# RP2040 register map
Vendor: Raspberry Pi; Series: RP; File version: 0.1
CPU: CM0PLUS r0p1, little endian, MPU, no FPU, VTOR, 2 interrupt priority bits, 32 interrupts
Registers are 32-bit, read-write, reset 0x0 unless marked. A register's access mark holds for its fields unless they carry their own. Offsets are from the block's base; [hi:lo] are bit positions; {n}, {i} and the like mark numbered series; 'fields as' and 'values as' point back to an identical list; <NAME> marks a mode.

## PADS_BANK0
Base 0x4001C000
0x00 VOLTAGE_SELECT — Voltage select. Per bank control
  [0] VOLTAGE_SELECT
    0=3v3 (Set voltage to 3.3V (DVDD >= 2V5)); 1=1v8 (Set voltage to 1.8V (DVDD <= 1V8))
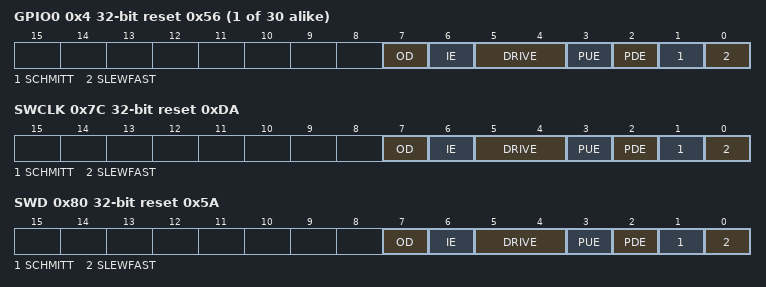
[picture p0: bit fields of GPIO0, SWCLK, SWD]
{0x4+4i} GPIO{i} reset 0x56 (i=0..29) — Pad control register
  [7] OD — Output disable. Has priority over output enable from peripherals
  [6] IE — Input enable
  [5:4] DRIVE — Drive strength.
    0=2mA; 1=4mA; 2=8mA; 3=12mA
  [3] PUE — Pull up enable
  [2] PDE — Pull down enable
  [1] SCHMITT — Enable schmitt trigger
  [0] SLEWFAST — Slew rate control. 1 = Fast, 0 = Slow
0x7C SWCLK reset 0xDA — Pad control register
  fields as GPIO0
0x80 SWD reset 0x5A — Pad control register
  fields as GPIO0

## PADS_QSPI
Base 0x40020000
0x00 VOLTAGE_SELECT — Voltage select. Per bank control
  [0] VOLTAGE_SELECT
    0=3v3 (Set voltage to 3.3V (DVDD >= 2V5)); 1=1v8 (Set voltage to 1.8V (DVDD <= 1V8))
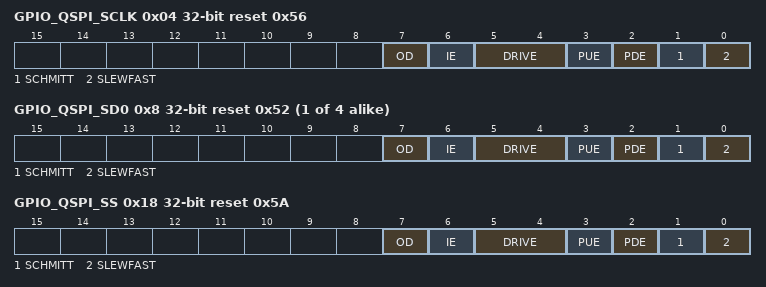
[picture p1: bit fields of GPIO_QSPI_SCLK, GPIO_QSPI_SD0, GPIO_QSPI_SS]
0x04 GPIO_QSPI_SCLK reset 0x56 — Pad control register
  [7] OD — Output disable. Has priority over output enable from peripherals
  [6] IE — Input enable
  [5:4] DRIVE — Drive strength.
    0=2mA; 1=4mA; 2=8mA; 3=12mA
  [3] PUE — Pull up enable
  [2] PDE — Pull down enable
  [1] SCHMITT — Enable schmitt trigger
  [0] SLEWFAST — Slew rate control. 1 = Fast, 0 = Slow
{0x8+4i} GPIO_QSPI_SD{i} reset 0x52 (i=0..3) — Pad control register
  fields as GPIO_QSPI_SCLK
0x18 GPIO_QSPI_SS reset 0x5A — Pad control register
  fields as GPIO_QSPI_SCLK

## PLL_SYS
Base 0x40028000
Same registers: PLL_USB 0x4002C000
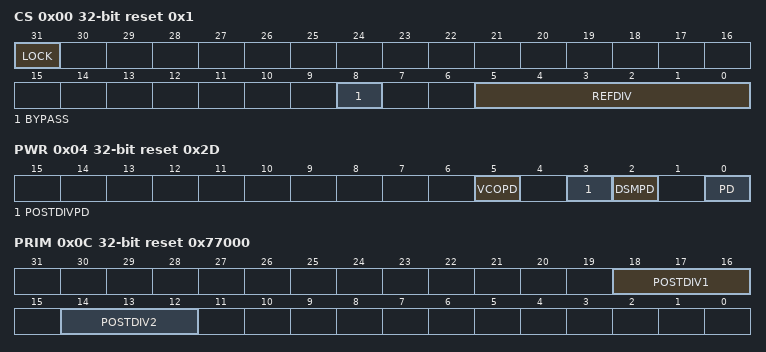
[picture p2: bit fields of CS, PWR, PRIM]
0x00 CS reset 0x1 — Control and Status GENERAL CONSTRAINTS: Reference clock frequency min=5MHz, max=800MHz Feedback divider min=16, max=320 VCO frequency min=750MHz, max=1600MHz
  [31] LOCK ro — PLL is locked
  [8] BYPASS — Passes the reference clock to the output instead of the divided VCO. The VCO continues to run so the user can switch between the reference clock and the divided VCO but the output will glitch when doing so.
  [5:0] REFDIV — Divides the PLL input reference clock. Behaviour is undefined for div=0. PLL output will be unpredictable during refdiv changes, wait for lock=1 before using it.
0x04 PWR reset 0x2D — Controls the PLL power modes.
  [5] VCOPD — PLL VCO powerdown To save power set high when PLL output not required or bypass=1.
  [3] POSTDIVPD — PLL post divider powerdown To save power set high when PLL output not required or bypass=1.
  [2] DSMPD — PLL DSM powerdown Nothing is achieved by setting this low.
  [0] PD — PLL powerdown To save power set high when PLL output not required.
0x08 FBDIV_INT — Feedback divisor (note: this PLL does not support fractional division)
  [11:0] FBDIV_INT — see ctrl reg description for constraints
0x0C PRIM reset 0x77000 — Controls the PLL post dividers for the primary output (note: this PLL does not have a secondary output) the primary output is driven from VCO divided by postdiv1*postdiv2
  [18:16] POSTDIV1 — divide by 1-7
  [14:12] POSTDIV2 — divide by 1-7

## PSM
Base 0x40010000
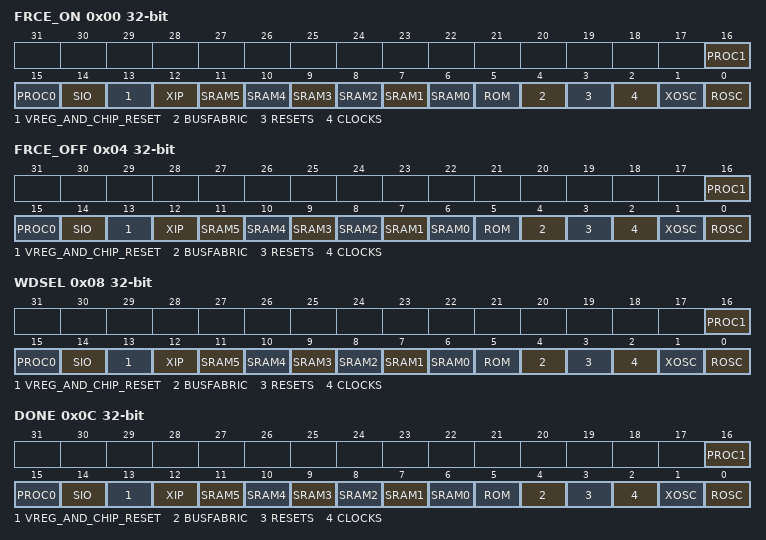
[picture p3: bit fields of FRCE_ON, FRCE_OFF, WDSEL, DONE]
0x00 FRCE_ON — Force block out of reset (i.e. power it on)
  [16] PROC1, [15] PROC0, [14] SIO, [13] VREG_AND_CHIP_RESET, [12] XIP, [n+6] SRAM{n} (n=0..5), [5] ROM, [4] BUSFABRIC, [3] RESETS, [2] CLOCKS, [1] XOSC, [0] ROSC
0x04 FRCE_OFF — Force into reset (i.e. power it off)
  fields as FRCE_ON
0x08 WDSEL — Set to 1 if this peripheral should be reset when the watchdog fires.
  fields as FRCE_ON
0x0C DONE — Indicates the peripheral's registers are ready to access.
  [16] PROC1 ro, [15] PROC0 ro, [14] SIO ro, [13] VREG_AND_CHIP_RESET ro, [12] XIP ro, [n+6] SRAM{n} ro (n=0..5), [5] ROM ro, [4] BUSFABRIC ro, [3] RESETS ro, [2] CLOCKS ro, [1] XOSC ro, [0] ROSC ro
